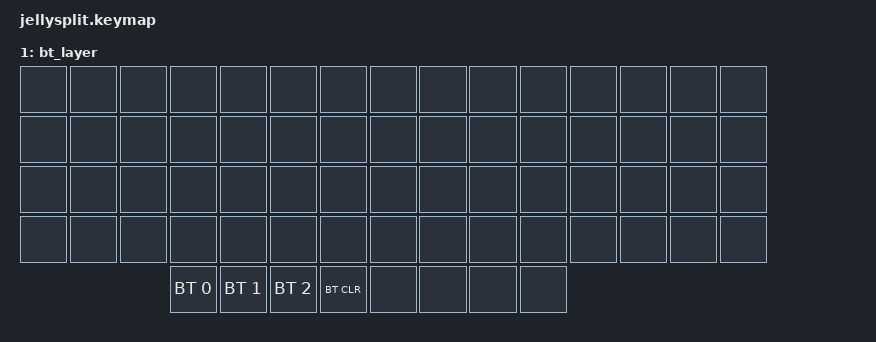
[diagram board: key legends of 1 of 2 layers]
#include <behaviors.dtsi>
#include <dt-bindings/zmk/keys.h>
#include <dt-bindings/zmk/bt.h>

/ {
    keymap {
        compatible = "zmk,keymap";

        default_layer {
            bindings = <
                &kp ESC     &kp GRAVE   &kp N1  &kp N2  &kp N3      &kp N4          &kp N5          &kp N6  &kp N7  &kp N8  &kp N9  &kp N0  &none   &none
                &mo 1       &kp TAB     &kp Q   &kp W   &kp E       &kp R           &kp T           &kp Y   &kp U   &kp I   &kp O   &kp P   &none   &none
                &mo 2       &kp CAPS    &kp A   &kp S   &kp D       &kp F           &kp G           &kp H   &kp J   &kp K   &kp L   &none   &none   &none
                &kp LCTRL   &kp LSHIFT  &kp Z   &kp X   &kp C       &kp V           &kp B           &kp N   &kp M   &none   &none   &none   &none   &none
                                                &mo 3   &kp LALT    &bt BT_SEL 0    &bt BT_CLR      &kp L   &kp O   &kp V   &kp E
            >;
        };

        bt_layer {
            bindings = <
                &none   &none   &none   &none           &none           &none           &none       &none   &none   &none   &none   &none   &none   &none   &none
                &none   &none   &none   &none           &none           &none           &none       &none   &none   &none   &none   &none   &none   &none   &none
                &none   &none   &none   &none           &none           &none           &none       &none   &none   &none   &none   &none   &none   &none   &none
                &none   &none   &none   &none           &none           &none           &none       &none   &none   &none   &none   &none   &none   &none   &none
                                        &bt BT_SEL 0    &bt BT_SEL 1    &bt BT_SEL 2    &bt BT_CLR  &none   &none   &none   &none
            >;
        };
    };
};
